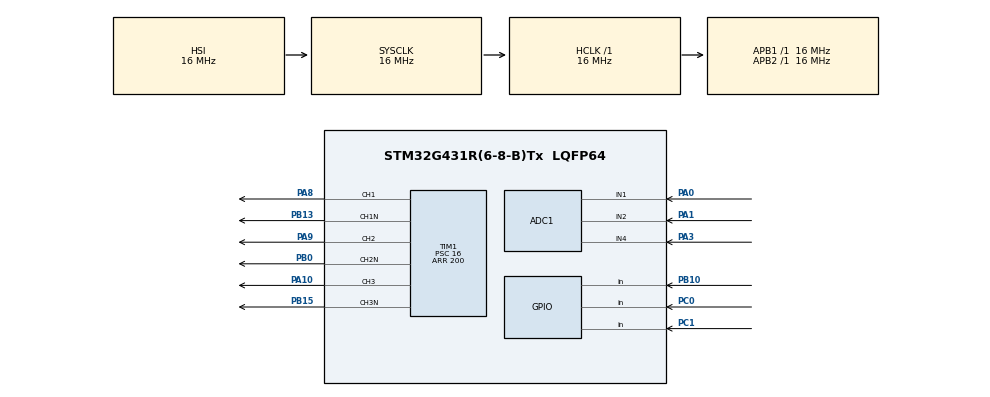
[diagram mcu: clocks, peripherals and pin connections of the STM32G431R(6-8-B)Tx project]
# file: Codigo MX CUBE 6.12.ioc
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ADC1.Channel-1\#ChannelRegularConversion=ADC_CHANNEL_1
ADC1.Channel-2\#ChannelRegularConversion=ADC_CHANNEL_2
ADC1.NbrOfConversion=2
ADC1.NbrOfConversionFlag=1
ADC1.OffsetNumber-1\#ChannelRegularConversion=ADC_OFFSET_NONE
ADC1.OffsetNumber-2\#ChannelRegularConversion=ADC_OFFSET_NONE
ADC1.Rank-1\#ChannelRegularConversion=1
ADC1.Rank-2\#ChannelRegularConversion=2
ADC1.SamplingTime-1\#ChannelRegularConversion=ADC_SAMPLETIME_12CYCLES_5
ADC1.SamplingTime-2\#ChannelRegularConversion=ADC_SAMPLETIME_12CYCLES_5
ADC1.master=1
Mcu.Family=STM32G4
Mcu.Name=STM32G431R(6-8-B)Tx
Mcu.Package=LQFP64
NVIC.PriorityGroup=NVIC_PRIORITYGROUP_4
PA0.Mode=IN1-Single-Ended
PA0.Signal=ADC1_IN1
PA1.Mode=IN2-Single-Ended
PA1.Signal=ADC1_IN2
PA10.Signal=S_TIM1_CH3
PA3.Mode=IN4-Single-Ended
PA3.Signal=ADC1_IN4
PA8.Signal=S_TIM1_CH1
PA9.Signal=S_TIM1_CH2
PB0.Mode=PWM Generation2 CH2 CH2N
PB0.Signal=TIM1_CH2N
PB10.GPIO_PuPd=GPIO_PULLUP
PB10.Signal=GPIO_Input
PB13.Mode=PWM Generation1 CH1 CH1N
PB13.Signal=TIM1_CH1N
PB15.Mode=PWM Generation3 CH3 CH3N
PB15.Signal=TIM1_CH3N
PC0.GPIO_PuPd=GPIO_PULLUP
PC0.Signal=GPIO_Input
PC1.GPIO_PuPd=GPIO_PULLUP
PC1.Signal=GPIO_Input
ProjectManager.HeapSize=0x200
ProjectManager.StackSize=0x400
ProjectManager.TargetToolchain=STM32CubeIDE
RCC.AHBFreq_Value=16000000
RCC.APB1Freq_Value=16000000
RCC.APB1TimFreq_Value=16000000
RCC.APB2Freq_Value=16000000
RCC.APB2TimFreq_Value=16000000
RCC.CortexFreq_Value=16000000
RCC.EXTERNAL_CLOCK_VALUE=12288000
RCC.HCLKFreq_Value=16000000
RCC.HSE_VALUE=8000000
RCC.HSI48_VALUE=48000000
RCC.HSI_VALUE=16000000
RCC.LSE_VALUE=32768
RCC.SYSCLKFreq_VALUE=16000000
RCC.USBFreq_Value=64000000
RCC.VCOOutputFreq_Value=128000000
SH.S_TIM1_CH1.0=TIM1_CH1,PWM Generation1 CH1 CH1N
SH.S_TIM1_CH2.0=TIM1_CH2,PWM Generation2 CH2 CH2N
SH.S_TIM1_CH3.0=TIM1_CH3,PWM Generation3 CH3 CH3N
TIM1.Channel-PWM\ Generation1\ CH1\ CH1N=TIM_CHANNEL_1
TIM1.Channel-PWM\ Generation2\ CH2\ CH2N=TIM_CHANNEL_2
TIM1.Channel-PWM\ Generation3\ CH3\ CH3N=TIM_CHANNEL_3
TIM1.PeriodNoDither=200
TIM1.Prescaler=16
VP_SYS_VS_DBSignals.Mode=DisableDeadBatterySignals
board=custom

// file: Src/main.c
/* USER CODE BEGIN Header */
/**
  ******************************************************************************
  * @file           : main.c
  * @brief          : Main program body
  ******************************************************************************
  * @attention
  *
  * Copyright (c) 2025 STMicroelectronics.
  * All rights reserved.
  *
  * This software is licensed under terms that can be found in the LICENSE file
  * in the root directory of this software component.
  * If no LICENSE file comes with this software, it is provided AS-IS.
  *
  ******************************************************************************
  */
/* USER CODE END Header */
#include "main.h"

ADC_HandleTypeDef hadc1;
DMA_HandleTypeDef hdma_adc1;

TIM_HandleTypeDef htim1;

/* USER CODE BEGIN PV */
#define NumeroCanaisADC 3
uint16_t leiturasADC[NumeroCanaisADC];
uint16_t* LeituraPedal = &leiturasADC[0];//Leitura do pedal
uint16_t* LeituraVEL_CI = &leiturasADC[1];//Leitura MC33039 (velocidade do motor com base nos sensores hall)
uint16_t* LeituraCorrente_CI = &leiturasADC[2];//Leitura ACS712 (Leitura de corrente saindo da bateria)
/* USER CODE END PV */

void SystemClock_Config(void);
static void MX_GPIO_Init(void);
static void MX_DMA_Init(void);
static void MX_ADC1_Init(void);
static void MX_TIM1_Init(void);

int main(void)
{

  /* MCU Configuration--------------------------------------------------------*/

  /* Reset of all peripherals, Initializes the Flash interface and the Systick. */
  HAL_Init();

  /* Configure the system clock */
  SystemClock_Config();

  /* Initialize all configured peripherals */
  MX_GPIO_Init();
  MX_DMA_Init();
  MX_ADC1_Init();
  MX_TIM1_Init();
  /* USER CODE BEGIN 2 */
  HAL_ADC_Start_DMA(&hadc1, leiturasADC, NumeroCanaisADC);

  /* USER CODE END 2 */

  /* Infinite loop */
  while (1)
  {

  }
}

void SystemClock_Config(void)
{
  RCC_OscInitTypeDef RCC_OscInitStruct = {0};
  RCC_ClkInitTypeDef RCC_ClkInitStruct = {0};

  /** Configure the main internal regulator output voltage
  */
  HAL_PWREx_ControlVoltageScaling(PWR_REGULATOR_VOLTAGE_SCALE1);

  /** Initializes the RCC Oscillators according to the specified parameters
  * in the RCC_OscInitTypeDef structure.
  */
  RCC_OscInitStruct.OscillatorType = RCC_OSCILLATORTYPE_HSI;
  RCC_OscInitStruct.HSIState = RCC_HSI_ON;
  RCC_OscInitStruct.HSICalibrationValue = RCC_HSICALIBRATION_DEFAULT;
  RCC_OscInitStruct.PLL.PLLState = RCC_PLL_NONE;
  if (HAL_RCC_OscConfig(&RCC_OscInitStruct) != HAL_OK)
  {
    Error_Handler();
  }

  /** Initializes the CPU, AHB and APB buses clocks
  */
  RCC_ClkInitStruct.ClockType = RCC_CLOCKTYPE_HCLK|RCC_CLOCKTYPE_SYSCLK
                              |RCC_CLOCKTYPE_PCLK1|RCC_CLOCKTYPE_PCLK2;
  RCC_ClkInitStruct.SYSCLKSource = RCC_SYSCLKSOURCE_HSI;
  RCC_ClkInitStruct.AHBCLKDivider = RCC_SYSCLK_DIV1;
  RCC_ClkInitStruct.APB1CLKDivider = RCC_HCLK_DIV1;
  RCC_ClkInitStruct.APB2CLKDivider = RCC_HCLK_DIV1;

  if (HAL_RCC_ClockConfig(&RCC_ClkInitStruct, FLASH_LATENCY_0) != HAL_OK)
  {
    Error_Handler();
  }
}

static void MX_ADC1_Init(void)
{

  ADC_MultiModeTypeDef multimode = {0};
  ADC_ChannelConfTypeDef sConfig = {0};

  /** Common config
  */
  hadc1.Instance = ADC1;
  hadc1.Init.ClockPrescaler = ADC_CLOCK_SYNC_PCLK_DIV2;
  hadc1.Init.Resolution = ADC_RESOLUTION_12B;
  hadc1.Init.DataAlign = ADC_DATAALIGN_RIGHT;
  hadc1.Init.GainCompensation = 0;
  hadc1.Init.ScanConvMode = ADC_SCAN_ENABLE;
  hadc1.Init.EOCSelection = ADC_EOC_SINGLE_CONV;
  hadc1.Init.LowPowerAutoWait = DISABLE;
  hadc1.Init.ContinuousConvMode = ENABLE;
  hadc1.Init.NbrOfConversion = 3;
  hadc1.Init.DiscontinuousConvMode = DISABLE;
  hadc1.Init.ExternalTrigConv = ADC_SOFTWARE_START;
  hadc1.Init.ExternalTrigConvEdge = ADC_EXTERNALTRIGCONVEDGE_NONE;
  hadc1.Init.DMAContinuousRequests = ENABLE;
  hadc1.Init.Overrun = ADC_OVR_DATA_PRESERVED;
  hadc1.Init.OversamplingMode = DISABLE;
  if (HAL_ADC_Init(&hadc1) != HAL_OK)
  {
    Error_Handler();
  }

  /** Configure the ADC multi-mode
  */
  multimode.Mode = ADC_MODE_INDEPENDENT;
  if (HAL_ADCEx_MultiModeConfigChannel(&hadc1, &multimode) != HAL_OK)
  {
    Error_Handler();
  }

  /** Configure Regular Channel
  */
  sConfig.Channel = ADC_CHANNEL_1;
  sConfig.Rank = ADC_REGULAR_RANK_1;
  sConfig.SamplingTime = ADC_SAMPLETIME_2CYCLES_5;
  sConfig.SingleDiff = ADC_SINGLE_ENDED;
  sConfig.OffsetNumber = ADC_OFFSET_NONE;
  sConfig.Offset = 0;
  if (HAL_ADC_ConfigChannel(&hadc1, &sConfig) != HAL_OK)
  {
    Error_Handler();
  }

  /** Configure Regular Channel
  */
  sConfig.Channel = ADC_CHANNEL_2;
  sConfig.Rank = ADC_REGULAR_RANK_2;
  if (HAL_ADC_ConfigChannel(&hadc1, &sConfig) != HAL_OK)
  {
    Error_Handler();
  }

  /** Configure Regular Channel
  */
  sConfig.Channel = ADC_CHANNEL_4;
  sConfig.Rank = ADC_REGULAR_RANK_3;
  if (HAL_ADC_ConfigChannel(&hadc1, &sConfig) != HAL_OK)
  {
    Error_Handler();
  }

}

static void MX_TIM1_Init(void)
{

  TIM_MasterConfigTypeDef sMasterConfig = {0};
  TIM_OC_InitTypeDef sConfigOC = {0};
  TIM_BreakDeadTimeConfigTypeDef sBreakDeadTimeConfig = {0};

  htim1.Instance = TIM1;
  htim1.Init.Prescaler = 16-1;
  htim1.Init.CounterMode = TIM_COUNTERMODE_UP;
  htim1.Init.Period = 100;
  htim1.Init.ClockDivision = TIM_CLOCKDIVISION_DIV1;
  htim1.Init.RepetitionCounter = 0;
  htim1.Init.AutoReloadPreload = TIM_AUTORELOAD_PRELOAD_DISABLE;
  if (HAL_TIM_PWM_Init(&htim1) != HAL_OK)
  {
    Error_Handler();
  }
  sMasterConfig.MasterOutputTrigger = TIM_TRGO_RESET;
  sMasterConfig.MasterOutputTrigger2 = TIM_TRGO2_RESET;
  sMasterConfig.MasterSlaveMode = TIM_MASTERSLAVEMODE_DISABLE;
  if (HAL_TIMEx_MasterConfigSynchronization(&htim1, &sMasterConfig) != HAL_OK)
  {
    Error_Handler();
  }
  sConfigOC.OCMode = TIM_OCMODE_PWM1;
  sConfigOC.Pulse = 0;
  sConfigOC.OCPolarity = TIM_OCPOLARITY_HIGH;
  sConfigOC.OCNPolarity = TIM_OCNPOLARITY_HIGH;
  sConfigOC.OCFastMode = TIM_OCFAST_DISABLE;
  sConfigOC.OCIdleState = TIM_OCIDLESTATE_RESET;
  sConfigOC.OCNIdleState = TIM_OCNIDLESTATE_RESET;
  if (HAL_TIM_PWM_ConfigChannel(&htim1, &sConfigOC, TIM_CHANNEL_1) != HAL_OK)
  {
    Error_Handler();
  }
  if (HAL_TIM_PWM_ConfigChannel(&htim1, &sConfigOC, TIM_CHANNEL_2) != HAL_OK)
  {
    Error_Handler();
  }
  if (HAL_TIM_PWM_ConfigChannel(&htim1, &sConfigOC, TIM_CHANNEL_3) != HAL_OK)
  {
    Error_Handler();
  }
  sBreakDeadTimeConfig.OffStateRunMode = TIM_OSSR_DISABLE;
  sBreakDeadTimeConfig.OffStateIDLEMode = TIM_OSSI_DISABLE;
  sBreakDeadTimeConfig.LockLevel = TIM_LOCKLEVEL_OFF;
  sBreakDeadTimeConfig.DeadTime = 0;
  sBreakDeadTimeConfig.BreakState = TIM_BREAK_DISABLE;
  sBreakDeadTimeConfig.BreakPolarity = TIM_BREAKPOLARITY_HIGH;
  sBreakDeadTimeConfig.BreakFilter = 0;
  sBreakDeadTimeConfig.BreakAFMode = TIM_BREAK_AFMODE_INPUT;
  sBreakDeadTimeConfig.Break2State = TIM_BREAK2_DISABLE;
  sBreakDeadTimeConfig.Break2Polarity = TIM_BREAK2POLARITY_HIGH;
  sBreakDeadTimeConfig.Break2Filter = 0;
  sBreakDeadTimeConfig.Break2AFMode = TIM_BREAK_AFMODE_INPUT;
  sBreakDeadTimeConfig.AutomaticOutput = TIM_AUTOMATICOUTPUT_DISABLE;
  if (HAL_TIMEx_ConfigBreakDeadTime(&htim1, &sBreakDeadTimeConfig) != HAL_OK)
  {
    Error_Handler();
  }
  HAL_TIM_MspPostInit(&htim1);

}

static void MX_DMA_Init(void)
{

  /* DMA controller clock enable */
  __HAL_RCC_DMAMUX1_CLK_ENABLE();
  __HAL_RCC_DMA1_CLK_ENABLE();

  /* DMA interrupt init */
  /* DMA1_Channel1_IRQn interrupt configuration */
  HAL_NVIC_SetPriority(DMA1_Channel1_IRQn, 0, 0);
  HAL_NVIC_EnableIRQ(DMA1_Channel1_IRQn);

}

static void MX_GPIO_Init(void)
{
  GPIO_InitTypeDef GPIO_InitStruct = {0};

  /* GPIO Ports Clock Enable */
  __HAL_RCC_GPIOC_CLK_ENABLE();
  __HAL_RCC_GPIOA_CLK_ENABLE();
  __HAL_RCC_GPIOB_CLK_ENABLE();

  /*Configure GPIO pins : PC13 PC0 PC1 */
  GPIO_InitStruct.Pin = GPIO_PIN_13|GPIO_PIN_0|GPIO_PIN_1;
  GPIO_InitStruct.Mode = GPIO_MODE_INPUT;
  GPIO_InitStruct.Pull = GPIO_NOPULL;
  HAL_GPIO_Init(GPIOC, &GPIO_InitStruct);

}

void Error_Handler(void)
{
  __disable_irq();
  while (1)
  {
  }
}
